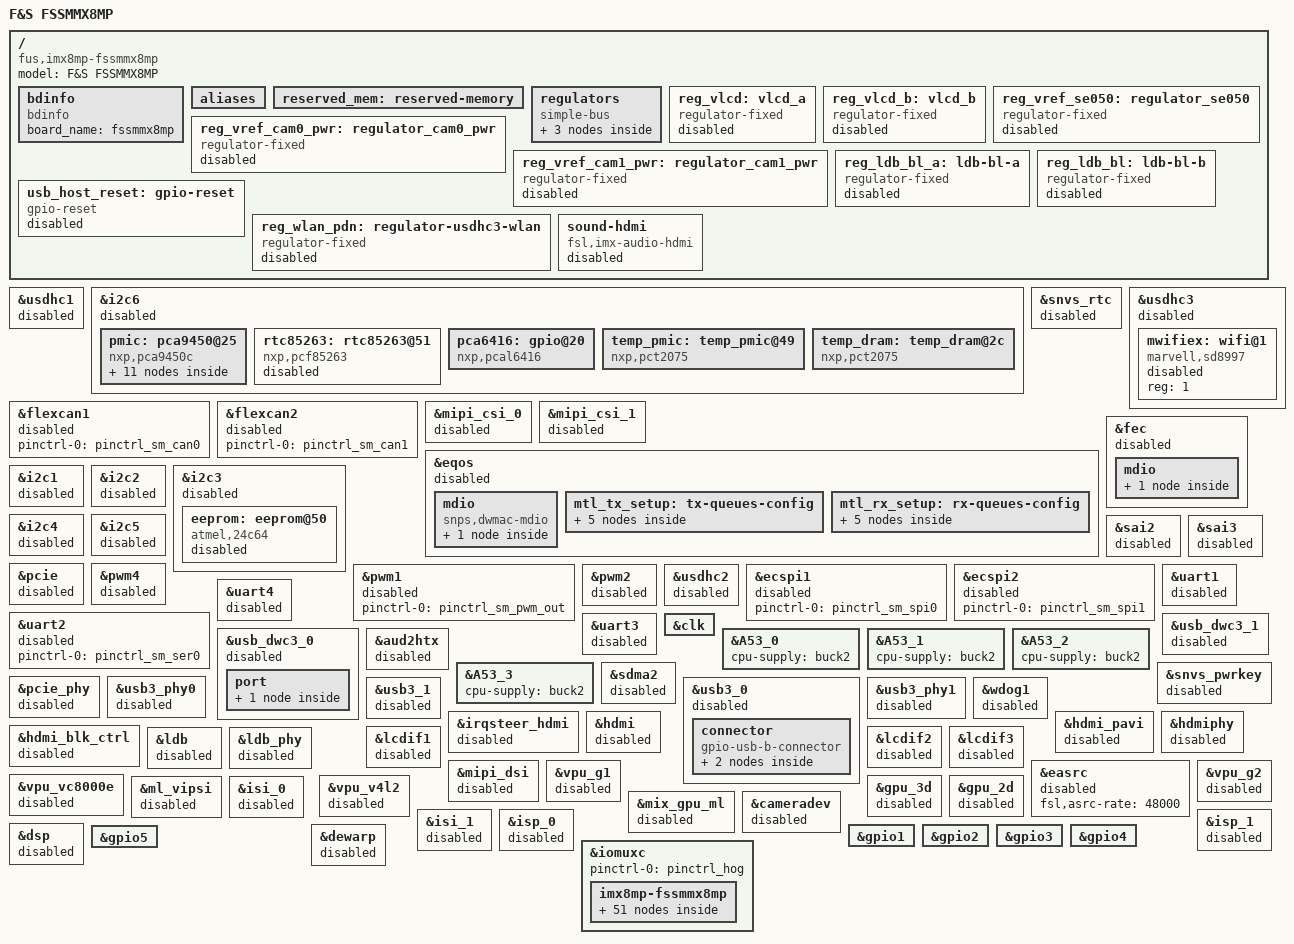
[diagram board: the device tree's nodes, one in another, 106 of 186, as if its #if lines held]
/*
 * Copyright 2024 F&S Elektronik Systeme GmbH
 *
 * This program is free software; you can redistribute it and/or modify
 * it under the terms of the GNU General Public License version 2 as
 * published by the Free Software Foundation.
 *
 * This program is distributed in the hope that it will be useful,
 * but WITHOUT ANY WARRANTY; without even the implied warranty of
 * MERCHANTABILITY or FITNESS FOR A PARTICULAR PURPOSE.  See the
 * GNU General Public License for more details.
 */

#include <dt-bindings/usb/pd.h>
#include <dt-bindings/pwm/pwm.h>
#include <dt-bindings/rtc/nxp,pcf85263.h>
#include <dt-bindings/phy/phy-imx8-pcie.h>

/* SOC-nodes to SMARC-nodes */

/* Internal nodes */
emmc: &usdhc1 {};
i2c_int: &i2c6 {};
rtc_soc: &snvs_rtc {};
sd_wlan: &usdhc3 {};

/* External nodes */
sm_can0: &flexcan1 {};
sm_can1: &flexcan2 {};
sm_csi0: &mipi_csi_0 {};
sm_csi1: &mipi_csi_1 {};
sm_gbe0: &eqos {};
sm_gbe1: &fec {};
sm_i2c_cam0: &i2c1 {};
sm_i2c_cam1: &i2c2 {};
sm_i2c_gp: &i2c3 {};
sm_i2c_pm: &i2c4 {};
sm_i2c_lcd: &i2c5 {};
sm_i2s0: &sai2 {};
sm_i2s2: &sai3 {};
sm_pcie: &pcie {};
sm_pwm_out: &pwm1 {};
sm_lcd0_bklt_pwm: &pwm4 {};
sm_lcd1_bklt_pwm: &pwm2 {};
sm_sdio: &usdhc2 {};
sm_spi0: &ecspi1 {};
sm_spi1: &ecspi2 {};
sm_ser0: &uart2 {};
sm_ser1: &uart1 {};
sm_ser2: &uart4 {};
sm_ser3: &uart3 {};
sm_usb0: &usb_dwc3_0 {};
sm_usb1: &usb_dwc3_1 {};
/* sm_usb2: sm_usb1 over HUB if mounted */
/* sm_usb3: sm_usb1 over HUB if mounted */
/* sm_usb4: sm_usb1 over HUB if mounted */

/ {
	model = "F&S FSSMMX8MP";
	compatible = "fus,imx8mp-fssmmx8mp", "fsl,imx8mp";

	bdinfo: bdinfo {
		compatible = "bdinfo";
		board_name = "fssmmx8mp";
	};

	aliases {
		ethernet0 = &eqos;
		ethernet1 = &fec;
		spi0 = &ecspi1;
		spi1 = &ecspi2;
		i2c0 = &i2c1;
		i2c1 = &i2c2;
		i2c2 = &i2c3;
		i2c3 = &i2c4;
		i2c4 = &i2c5;
		i2c5 = &i2c6;
		eeprom = &eeprom;
		wlan = &mwifiex;
		wlan-reset = &reg_wlan_pdn;
	};

	reserved_mem: reserved-memory {
		/* remove this node because the region used
		 * only by tuning tool
		 * */
		/delete-node/isp0@94400000;
		/* remove these nodes because we reserve
		 * our own memory regions
		 * */
		/delete-node/dsp@92400000;
		/delete-node/dsp_reserved_heap@93400000;
		/delete-node/vdev0vring0@942f0000;
		/delete-node/vdev0vring1@942f8000;
		/delete-node/vdev0buffer@94300000;
	};

	regulators {
		compatible = "simple-bus";
		#address-cells = <1>;
		#size-cells = <0>;

		reg_vref_1v2: regulator_1v2 {
			compatible = "regulator-fixed";
			regulator-name = "vref-1V2";
			regulator-min-microvolt = <1200000>;
			regulator-max-microvolt = <1200000>;
			regulator-always-on;
		};

		reg_vref_1v8: regulator_1v8 {
			compatible = "regulator-fixed";
			regulator-name = "vref-1V8";
			regulator-min-microvolt = <1800000>;
			regulator-max-microvolt = <1800000>;
			regulator-always-on;
		};

		reg_vref_3v3: regulator_3v3 {
			compatible = "regulator-fixed";
			regulator-name = "vref-3V3";
			regulator-min-microvolt = <3300000>;
			regulator-max-microvolt = <3300000>;
			regulator-always-on;
		};
	};

	/* LCD0 power on voltage */
	/omit-if-no-ref/
	reg_vlcd: vlcd_a {
		compatible = "regulator-fixed";
		regulator-name = "LCD0_VDD_EN";
		pinctrl-names = "default";
		pinctrl-0 = <&pinctrl_vlcd_a_on>;
		gpio = <&gpio4 20 GPIO_ACTIVE_HIGH>;
		regulator-min-microvolt = <3300000>;
		regulator-max-microvolt = <3300000>;
		enable-active-high;
		status = "disabled";
	};

	/* LCD1 power on voltage */
	/omit-if-no-ref/
	reg_vlcd_b: vlcd_b {
		compatible = "regulator-fixed";
		regulator-name = "LCD1_VDD_EN";
		pinctrl-names = "default";
		pinctrl-0 = <&pinctrl_vlcd_b_on>;
		gpio = <&gpio4 2 GPIO_ACTIVE_HIGH>;
		regulator-min-microvolt = <3300000>;
		regulator-max-microvolt = <3300000>;
		enable-active-high;
		status = "disabled";
	};

	/* SE050 power on voltage */
	reg_vref_se050: regulator_se050 {
		compatible = "regulator-fixed";
		regulator-name = "SE050_ENA";
		pinctrl-names = "default";
		pinctrl-0 = <&pinctrl_se050>;
		gpio = <&gpio1 0 GPIO_ACTIVE_HIGH>;
		regulator-min-microvolt = <1800000>;
		regulator-max-microvolt = <1800000>;
		regulator-always-on;
		enable-active-high;
		status = "disabled";
	};

	/* CAM_PWR# power on voltage */
	reg_vref_cam0_pwr: regulator_cam0_pwr {
		compatible = "regulator-fixed";
		regulator-name = "CAM0_PWR";
		pinctrl-names = "default";
		regulator-min-microvolt = <1800000>;
		regulator-max-microvolt = <1800000>;
		regulator-boot-on;
		regulator-always-on;
		status = "disabled";
	};

	/* CAM_PWR# power on voltage */
	reg_vref_cam1_pwr: regulator_cam1_pwr {
		compatible = "regulator-fixed";
		regulator-name = "CAM1_PWR";
		pinctrl-names = "default";
		regulator-min-microvolt = <1800000>;
		regulator-max-microvolt = <1800000>;
		regulator-boot-on;
		regulator-always-on;
		status = "disabled";
	};

	reg_ldb_bl_a: ldb-bl-a {
		compatible = "regulator-fixed";
		regulator-name = "ldb-bl0";
		pinctrl-names = "default";
		pinctrl-0 = <&pinctrl_ldb_bl_a>;
		gpio = <&gpio4 1 GPIO_ACTIVE_HIGH>;
		regulator-min-microvolt = <3300000>;
		regulator-max-microvolt = <3300000>;
		enable-active-high;
		status = "disabled";
	};

	reg_ldb_bl: ldb-bl-b {
		compatible = "regulator-fixed";
		regulator-name = "ldb-bl1";
		pinctrl-names = "default";
		pinctrl-0 = <&pinctrl_ldb_bl_b>;
		gpio = <&gpio4 3 GPIO_ACTIVE_HIGH>;
		regulator-min-microvolt = <3300000>;
		regulator-max-microvolt = <3300000>;
		enable-active-high;
		status = "disabled";
	};

	usb_host_reset: gpio-reset {
		compatible = "gpio-reset";
		reset-gpios = <&pca6416 14 GPIO_ACTIVE_LOW>;
		reset-delay-us = <10>;
		#reset-cells = <0>;
		status = "disabled";
	};

	reg_wlan_pdn: regulator-usdhc3-wlan {
		compatible = "regulator-fixed";
		regulator-name = "WLAN_RESET";
		pinctrl-names = "default";
		pinctrl-0 = <&pinctrl_wlan_pdn>;
		regulator-min-microvolt = <3300000>;
		regulator-max-microvolt = <3300000>;
		gpio = <&gpio4 18 GPIO_ACTIVE_HIGH>;
		off-on-delay-us = <1000>;
		enable-active-low;
		status = "disabled";
	};

	sound-hdmi {
		compatible = "fsl,imx-audio-hdmi";
		model = "audio-hdmi";
		audio-cpu = <&aud2htx>;
		hdmi-out;
		constraint-rate = <44100>, <88200>, <176400>,
				  <32000>, <48000>,
				  <96000>, <192000>;
		status = "disabled";
	};
};

&aud2htx {
	status = "disabled";
};

&clk {
	assigned-clocks = <&clk IMX8MP_CLK_A53_SRC>,
			  <&clk IMX8MP_CLK_A53_CORE>,
			  <&clk IMX8MP_CLK_NOC>,
			  <&clk IMX8MP_CLK_NOC_IO>,
			  <&clk IMX8MP_CLK_GIC>,
			  <&clk IMX8MP_CLK_AUDIO_AHB>,
			  <&clk IMX8MP_CLK_AUDIO_AXI_SRC>,
			  <&clk IMX8MP_AUDIO_PLL1>,
			  <&clk IMX8MP_AUDIO_PLL2>,
			  <&clk IMX8MP_VIDEO_PLL1>,
			  <&clk IMX8MP_CLK_CLKOUT1>;
	assigned-clock-rates = <0>, <0>,
			       <1000000000>,
			       <800000000>,
			       <500000000>,
			       <400000000>,
			       <800000000>,
			       <393216000>,
			       <361267200>,
			       <1039500000>,
			       <24576000>;

	init-on-array = <IMX8MP_CLK_HSIO_ROOT>, <IMX8MP_CLK_CLKOUT1>;
};

&A53_0 {
	cpu-supply = <&buck2>;
};

&A53_1 {
	cpu-supply = <&buck2>;
};

&A53_2 {
	cpu-supply = <&buck2>;
};

&A53_3 {
	cpu-supply = <&buck2>;
};

&sm_gbe0 {
	pinctrl-names = "default";
	pinctrl-0 = <&pinctrl_sm_gbe0>;
	phy-mode = "rgmii-id";
	phy-handle = <&ethphy0>;
	snps,force_thresh_dma_mode;
	snps,mtl-tx-config = <&mtl_tx_setup>;
	snps,mtl-rx-config = <&mtl_rx_setup>;
	status = "disabled";

	mdio {
		compatible = "snps,dwmac-mdio";
		#address-cells = <1>;
		#size-cells = <0>;

		ethphy0: ethernet-phy@4 {
			compatible = "ethernet-phy-ieee802.3-c22";
			reg = <4>;
			rtl821x,clkout-disable;
			rtl821x,aldps-enable;
			rtl821x,ssc-rxc-enable;
			rtl821x,ssc-sysclk-enable;
			rtl821x,ssc-clkout-enable;
			rtl821x,led-link = <2>; // LED2 for link indication
			rtl821x,led-act = <0>; // LED0 for activity
			reset-gpios = <&pca6416 11 GPIO_ACTIVE_LOW>;
			reset-assert-us = <10000>;
			reset-deassert-us = <100000>;
			interrupt-parent = <&gpio1>;
			interrupts = <6 IRQ_TYPE_LEVEL_LOW>;
			eee-broken-1000t;
		};
	};

	mtl_tx_setup: tx-queues-config {
		snps,tx-queues-to-use = <5>;
		snps,tx-sched-sp;

		queue0 {
			snps,dcb-algorithm;
			snps,priority = <0x1>;
		};

		queue1 {
			snps,dcb-algorithm;
			snps,priority = <0x2>;
		};

		queue2 {
			snps,dcb-algorithm;
			snps,priority = <0x4>;
		};

		queue3 {
			snps,dcb-algorithm;
			snps,priority = <0x8>;
		};

		queue4 {
			snps,dcb-algorithm;
			snps,priority = <0xf0>;
		};
	};

	mtl_rx_setup: rx-queues-config {
		snps,rx-queues-to-use = <5>;
		snps,rx-sched-sp;

		queue0 {
			snps,dcb-algorithm;
			snps,priority = <0x1>;
			snps,map-to-dma-channel = <0>;
		};

		queue1 {
			snps,dcb-algorithm;
			snps,priority = <0x2>;
			snps,map-to-dma-channel = <1>;
		};

		queue2 {
			snps,dcb-algorithm;
			snps,priority = <0x4>;
			snps,map-to-dma-channel = <2>;
		};

		queue3 {
			snps,dcb-algorithm;
			snps,priority = <0x8>;
			snps,map-to-dma-channel = <3>;
		};

		queue4 {
			snps,dcb-algorithm;
			snps,priority = <0xf0>;
			snps,map-to-dma-channel = <4>;
		};
	};
};

&sm_gbe1 {
	pinctrl-names = "default";
	pinctrl-0 = <&pinctrl_sm_gbe1>;
	phy-mode = "rgmii-id";
	phy-handle = <&ethphy1>;
	fsl,magic-packet;
	status = "disabled";

	mdio {
		#address-cells = <1>;
		#size-cells = <0>;

		ethphy1: ethernet-phy@5 {
			compatible = "ethernet-phy-ieee802.3-c22";
			reg = <5>;
			rtl821x,clkout-disable;
			rtl821x,aldps-enable;
			rtl821x,ssc-rxc-enable;
			rtl821x,ssc-sysclk-enable;
			rtl821x,ssc-clkout-enable;
			rtl821x,led-link = <2>; // LED2 for link indication
			rtl821x,led-act = <0>; // LED0 for activity
			reset-gpios = <&pca6416 12 GPIO_ACTIVE_LOW>;
			reset-assert-us = <10000>;
			reset-deassert-us = <100000>;
			interrupt-parent = <&gpio5>;
			interrupts = <1 IRQ_TYPE_LEVEL_LOW>;
			eee-broken-1000t;
		};
	};
};

#ifdef CONFIG_FSSMMX8MP_PWM_OUT
&sm_pwm_out {
	pinctrl-names = "default";
	pinctrl-0 = <&pinctrl_sm_pwm_out>;
	status = "disabled";
};
#endif /* CONFIG_FSSMMX8MP_PWM_OUT */

#ifdef CONFIG_FSSMMX8MP_LCD0_BKLT
&sm_lcd0_bklt_pwm {
	pinctrl-names = "default";
	pinctrl-0 = <&pinctrl_sm_lcd0_bklt_pwm>;
	#pwm-cells = <3>;
	keep-power;
	status = "disabled";
};
#endif /* CONFIG_FSSMMX8MP_LCD0_BKLT */

#ifdef CONFIG_FSSMMX8MP_LCD1_BKLT
&sm_lcd1_bklt_pwm {
	pinctrl-names = "default";
	pinctrl-0 = <&pinctrl_sm_lcd1_bklt_pwm>;
	#pwm-cells = <3>;
	keep-power;
	status = "disabled";
};
#endif /* CONFIG_FSSMMX8MP_LCD1_BKLT */

&snvs_pwrkey {
	status = "disabled";
};

/* Disable CPU RTC - external available */
&snvs_rtc {
	status = "disabled";
};

&sm_i2c_cam0 {
	clock-frequency = <400000>;
	pinctrl-names = "default";
	pinctrl-0 = <&pinctrl_sm_i2c_cam0>;
	status = "disabled";
};

&sm_i2c_cam1 {
	clock-frequency = <100000>;
	pinctrl-names = "default";
	pinctrl-0 = <&pinctrl_sm_i2c_cam1>;
	status = "disabled";
};

&sm_i2c_gp {
	clock-frequency = <400000>;
	pinctrl-names = "default";
	pinctrl-0 = <&pinctrl_sm_i2c_gp>;
	status = "disabled";

	/* EEPROM */
	eeprom: eeprom@50 {
		compatible = "atmel,24c64";
		reg = <0x50>;
		pagesize = <8>;
		vcc-supply = <&reg_vref_1v8>;
		status = "disabled";
	};
};

&sm_i2c_pm {
	clock-frequency = <400000>;
	pinctrl-names = "default";
	pinctrl-0 = <&pinctrl_sm_i2c_pm>;
	status = "disabled";
};

&sm_i2c_lcd {
	clock-frequency = <400000>;
	pinctrl-names = "default";
	pinctrl-0 = <&pinctrl_sm_i2c_lcd>;
	status = "disabled";
};

/* I2C_INT */
&i2c_int {
	clock-frequency = <400000>;
	pinctrl-names = "default";
	pinctrl-0 = <&pinctrl_i2c_int>;
	status = "disabled";

	pmic: pca9450@25 {
		reg = <0x25>;
		compatible = "nxp,pca9450c";
		pinctrl-names = "default";
		pinctrl-0 = <&pinctrl_pmic>;
		interrupt-parent = <&gpio4>;
		interrupts = <19 IRQ_TYPE_LEVEL_LOW>;

		regulators {
			buck1: BUCK1 {
				regulator-name = "BUCK1";
				regulator-min-microvolt = <600000>;
				regulator-max-microvolt = <2187500>;
				regulator-boot-on;
				regulator-always-on;
				regulator-ramp-delay = <3125>;
			};

			buck2: BUCK2 {
				regulator-name = "BUCK2";
				regulator-min-microvolt = <600000>;
				regulator-max-microvolt = <2187500>;
				regulator-boot-on;
				regulator-always-on;
				regulator-ramp-delay = <3125>;
				nxp,dvs-run-voltage = <950000>;
				nxp,dvs-standby-voltage = <850000>;
			};

			buck4: BUCK4 {
				regulator-name = "BUCK4";
				regulator-min-microvolt = <3300000>;
				regulator-max-microvolt = <3300000>;
				regulator-boot-on;
				regulator-always-on;
			};

			buck5: BUCK5 {
				regulator-name = "BUCK5";
				regulator-min-microvolt = <1800000>;
				regulator-max-microvolt = <1800000>;
				regulator-boot-on;
				regulator-always-on;
			};

			buck6: BUCK6 {
				regulator-name = "BUCK6";
				regulator-min-microvolt = <600000>;
				regulator-max-microvolt = <3400000>;
				regulator-boot-on;
				regulator-always-on;
			};

			ldo1: LDO1 {
				regulator-name = "LDO1";
				regulator-min-microvolt = <1600000>;
				regulator-max-microvolt = <3300000>;
				regulator-boot-on;
				regulator-always-on;
			};

			ldo2: LDO2 {
				regulator-name = "LDO";
				regulator-min-microvolt = <800000>;
				regulator-max-microvolt = <1150000>;
				regulator-boot-on;
				regulator-always-on;
			};

			ldo3: LDO3 {
				regulator-name = "LDO3";
				regulator-min-microvolt = <800000>;
				regulator-max-microvolt = <3300000>;
				regulator-boot-on;
				regulator-always-on;
			};

			ldo4: LDO4 {
				regulator-name = "LDO4";
				regulator-min-microvolt = <800000>;
				regulator-max-microvolt = <3300000>;
				regulator-boot-on;
				regulator-always-on;
			};

			ldo5: LDO5 {
				regulator-name = "LDO5";
				regulator-compatible = "ldo5";
				regulator-min-microvolt = <1800000>;
				regulator-max-microvolt = <3300000>;
				regulator-boot-on;
				regulator-always-on;
			};
		};
	};

	rtc85263: rtc85263@51 {
		compatible = "nxp,pcf85263";
		reg = <0x51>;
		clock-out = <PCF85263_CLK_OUT_32p768kHz>;

		quartz-load-capacitance = <PCF85263_QUARTZCAP_12p5pF>;
		quartz-drive-strength = <PCF85263_QUARTZDRIVE_LOW>;
		status = "disabled";
	};

	/* GPIO expander */
	pca6416: gpio@20 {
		compatible = "nxp,pcal6416";
		reg = <0x20>;
		pinctrl-names = "default";
		pinctrl-0 = <&pinctrl_pca6416>;
		vcc-supply = <&reg_vref_1v8>;
		gpio-controller;
		#gpio-cells = <2>;
		interrupt-parent = <&gpio4>;
		interrupts = <21 IRQ_TYPE_LEVEL_LOW>;
		reset-gpios = <&gpio4 22 GPIO_ACTIVE_LOW>;
		/* Enable Open-Drain for Port 0 and 1 */
		pcal6416,open-drain;
	};

	/* Temperature sensor 1 at PMIC */
	temp_pmic: temp_pmic@49 {
		compatible = "nxp,pct2075";
		reg = <0x49>;
		vs-supply = <&reg_vref_3v3>;
		#thermal-sensor-cells = <1>;
	};

	/* Temperature sensor 2 at DRAM */
	temp_dram: temp_dram@2c {
		compatible = "nxp,pct2075";
		reg = <0x2c>;
		vs-supply = <&reg_vref_3v3>;
		#thermal-sensor-cells = <1>;
	};
};

&sm_spi0 {
	#address-cells = <1>;
	#size-cells = <0>;
	pinctrl-names = "default";
	pinctrl-0 = <&pinctrl_sm_spi0>;
	status = "disabled";
};

&sm_spi1 {
	#address-cells = <1>;
	#size-cells = <0>;
	pinctrl-names = "default";
	pinctrl-0 = <&pinctrl_sm_spi1>;
	status = "disabled";
};

&sm_can0 {
	pinctrl-names = "default";
	pinctrl-0 = <&pinctrl_sm_can0>;
	status = "disabled";
};

&sm_can1 {
	pinctrl-names = "default";
	pinctrl-0 = <&pinctrl_sm_can1>;
	status = "disabled";
};

&sm_i2s0 {
	#sound-dai-cells = <0>;
	pinctrl-names = "default";
	pinctrl-0 = <&pinctrl_sm_i2s0>;
	assigned-clocks = <&clk IMX8MP_CLK_SAI2>;
	assigned-clock-parents = <&clk IMX8MP_AUDIO_PLL1_OUT>;
	assigned-clock-rates = <24576000>;
	clocks = <&audio_blk_ctrl IMX8MP_CLK_AUDIOMIX_SAI2_IPG>, <&clk IMX8MP_CLK_DUMMY>,
		 <&clk IMX8MP_CLK_CLKOUT1>, <&clk IMX8MP_CLK_DUMMY>,
		 <&clk IMX8MP_CLK_DUMMY>;
	clock-names = "bus", "mclk0", "mclk1", "mclk2", "mclk3";
	fsl,sai-mclk-direction-output;
	/* sai to clock and frame tx/rx master */
	fsl,txmasterflag = <1>; // SND_SOC_DAIFMT_CBM_CFM
	fsl,rxmasterflag = <1>; // SND_SOC_DAIFMT_CBM_CFM
	status = "disabled";
};

&sm_i2s2 {
	#sound-dai-cells = <0>;
	pinctrl-names = "default";
	pinctrl-0 = <&pinctrl_sm_i2s2>;
	assigned-clocks = <&clk IMX8MP_CLK_SAI3>;
	assigned-clock-parents = <&clk IMX8MP_AUDIO_PLL1_OUT>;
	assigned-clock-rates = <24576000>;
	clocks = <&audio_blk_ctrl IMX8MP_CLK_AUDIOMIX_SAI3_IPG>, <&clk IMX8MP_CLK_DUMMY>,
		 <&clk IMX8MP_CLK_CLKOUT1>, <&clk IMX8MP_CLK_DUMMY>,
		 <&clk IMX8MP_CLK_DUMMY>;
	clock-names = "bus", "mclk0", "mclk1", "mclk2", "mclk3";
	fsl,sai-mclk-direction-output;
	/* sai to clock and frame tx/rx master */
	fsl,txmasterflag = <1>; // SND_SOC_DAIFMT_CBM_CFM
	fsl,rxmasterflag = <1>; // SND_SOC_DAIFMT_CBM_CFM
	status = "disabled";
};

&sdma2 {
	status = "disabled";
};

&sm_ser1 {
	pinctrl-names = "default";
	pinctrl-0 = <&pinctrl_sm_ser1>;
	assigned-clocks = <&clk IMX8MP_CLK_UART1>;
	assigned-clock-parents = <&clk IMX8MP_SYS_PLL1_80M>;
	status = "disabled";
};

&sm_ser0 {
	/* console */
	pinctrl-names = "default";
	pinctrl-0 = <&pinctrl_sm_ser0>;
	status = "disabled";
};

&sm_ser3 {
	pinctrl-names = "default";
	pinctrl-0 = <&pinctrl_sm_ser3>;
	assigned-clocks = <&clk IMX8MP_CLK_UART3>;
	assigned-clock-parents = <&clk IMX8MP_SYS_PLL1_80M>;
	status = "disabled";
};

&sm_ser2 {
	pinctrl-names = "default";
	pinctrl-0 = <&pinctrl_sm_ser2>;
	assigned-clocks = <&clk IMX8MP_CLK_UART4>;
	assigned-clock-parents = <&clk IMX8MP_SYS_PLL1_80M>;
	status = "disabled";
};

&pcie {
	clkreq-gpio = <&pca6416 15 GPIO_ACTIVE_LOW>;
	reset-gpio = <&pca6416 13 GPIO_ACTIVE_LOW>;
	vpcie-supply = <&reg_vref_3v3>;
	status = "disabled";
};

&pcie_phy {
	fsl,refclk-pad-mode = <IMX8_PCIE_REFCLK_PAD_OUTPUT>;
	clocks = <&hsio_blk_ctrl>;
	clock-names = "ref";
	status = "disabled";
};

/* USB_A */
&usb3_phy0 {
	fsl,phy-tx-preemp-amp-tune = <3>;
	fsl,phy-tx-vref-tune = <0xb>;
	status = "disabled";
};

&usb3_0 {
	status = "disabled";

	connector {
		compatible = "gpio-usb-b-connector", "usb-b-connector";
		pinctrl-names = "default";
		pinctrl-0 = <&pinctrl_sm_usb0_id>;
		id-gpios = <&gpio1 10 GPIO_ACTIVE_HIGH>;

		port {
			connector_dr_sw: endpoint {
				remote-endpoint = <&usb3_drd_sw>;
			};
		};
	};
};

&sm_usb0 {
	pinctrl-names = "default";
	pinctrl-0 = <&pinctrl_sm_usb0_pwr>;
	dr_mode = "otg";
	hnp-disable;
	srp-disable;
	adp-disable;
	usb-role-switch;
	role-switch-default-mode = "none";
	status = "disabled";

	port {
		usb3_drd_sw: endpoint {
			remote-endpoint = <&connector_dr_sw>;
		};
	};
};

/* USB_B */
&usb3_phy1 {
	/* vbus-power-supply = <&ptn5110>; */
	fsl,phy-tx-vref-tune = <0xe>;
	fsl,phy-tx-preemp-amp-tune = <3>;
	fsl,phy-tx-vboost-level = <5>;
	fsl,phy-comp-dis-tune = <7>;
	fsl,pcs-tx-deemph-3p5db = <0x21>;
	fsl,phy-pcs-tx-swing-full = <0x7f>;
	status = "disabled";
};

&usb3_1 {
	status = "disabled";
};

&sm_usb1 {
	pinctrl-names = "default";
	pinctrl-0 = <&pinctrl_sm_usb1_pwr>;
	resets = <&usb_host_reset>;
	dr_mode = "host";
	status = "disabled";
};

/* SD_C - internal eMCC boot device */
&emmc {
	pinctrl-names = "default", "state_100mhz", "state_200mhz";
	pinctrl-0 = <&pinctrl_emmc>;
	pinctrl-1 = <&pinctrl_emmc_100mhz>;
	pinctrl-2 = <&pinctrl_emmc_200mhz>;
	non-removable;
	bus-width = <8>;
	status = "disabled";
};

/* SD_A - internal Micro-SD */
&sm_sdio {
	pinctrl-names = "default", "state_100mhz", "state_200mhz";
	pinctrl-0 = <&pinctrl_sm_sdio>;
	pinctrl-1 = <&pinctrl_sm_sdio_100mhz>;
	pinctrl-2 = <&pinctrl_sm_sdio_200mhz>;
	bus-width = <4>;
	status = "disabled";
};

/* SD_WLAN */
&sd_wlan {
	pinctrl-names = "default", "state_100mhz", "state_200mhz";
	pinctrl-0 = <&pinctrl_sd_wlan>;
	pinctrl-1 = <&pinctrl_sd_wlan_100mhz>;
	pinctrl-2 = <&pinctrl_sd_wlan_200mhz>;
	vmmc-supply = <&reg_wlan_pdn>;
	vqmmc-supply = <&reg_vref_1v8>;
	fsl,sdio-async-interrupt-enabled;
	pm-ignore-notify;
	keep-power-in-suspend;
	non-removable;
	cap-power-off-card;
	bus-width = <4>;
	status = "disabled";
	#address-cells = <1>;
	#size-cells = <0>;

	mwifiex: wifi@1 {
		compatible = "marvell,sd8997";
		reg = <1>;
		status = "disabled";
	};
};

&sm_csi0 {
	#address-cells = <1>;
	#size-cells = <0>;
	status = "disabled";
};

&sm_csi1 {
	#address-cells = <1>;
	#size-cells = <0>;
	status = "disabled";
};

&wdog1 {
	pinctrl-names = "default";
	pinctrl-0 = <&pinctrl_wdog>;
	fsl,ext-reset-output;
	status = "disabled";
};

&irqsteer_hdmi {
	status = "disabled";
};

&hdmi_pavi {
	status = "disabled";
};

&hdmi {
	status = "disabled";
};

&hdmiphy {
	status = "disabled";
};

&hdmi_blk_ctrl {
	status = "disabled";
};

&lcdif1 {
	status = "disabled";
};

&lcdif2 {
	status = "disabled";
};

&lcdif3 {
	status = "disabled";
	thres-low = <1 2>;             /* (FIFO * 1 / 2) */
	thres-high = <3 4>;             /* (FIFO * 3 / 4) */
};

&ldb {
	status = "disabled";
};

&ldb_phy {
	status = "disabled";
};

&mipi_dsi {
	status = "disabled";
};

&easrc {
	fsl,asrc-rate = <48000>;
	status = "disabled";
};

&vpu_g1 {
	status = "disabled";
};

&vpu_g2 {
	status = "disabled";
};

&vpu_vc8000e {
	status = "disabled";
};

&vpu_v4l2 {
	status = "disabled";
};

&gpu_3d {
	status = "disabled";
};

&gpu_2d {
	status = "disabled";
};

&ml_vipsi {
	status = "disabled";
};

&mix_gpu_ml {
	status = "disabled";
};

&cameradev {
	status = "disabled";
};

&isi_0 {
	status = "disabled";
	dma-coherent;
	bsl,dma-invalidate;
	fsl,chain_buf;
};

&isi_1 {
	status = "disabled";
	dma-coherent;
	bsl,dma-invalidate;
	fsl,chain_buf;
};

&isp_0 {
	/* remove this property because this region used
	 * only by tuning tool
	 */
	/delete-property/ memory-region;
	status = "disabled";
};

&isp_1 {
	status = "disabled";
};

&dsp {
	/delete-property/ memory-region;
	status = "disabled";
};

&dewarp {
	status = "disabled";
};

/* GPIO declarations */
&gpio1 {
	gpio-line-names =
	/* 0 */  "SE050_ENA", "WDT_TIME_OUT", "PMIC_WDOG", "SPI_B_CS1",
	/* 4 */  "SD_VSEL", "GPIO2", "ETH_A_PHY_IRQ", "GPIO1",
	/* 8 */  "GPIO3", "GPIO0", "USB_A_ID", "GPIO7",
	/* 12 */ "USB_A_PWREN_1V8", "USB_A_OC#_1V8", "USB_B_PWREN_1V8", "USB_B_OC#_1V8",
	/* 16 */ "ETH_A_RGMII_MDC", "ETH_A_RGMII_MDIO", "ETH_A_RGMII_TXD3", "ETH_A_RGMII_TXD2",
	/* 20 */ "ETH_A_RGMII_TXD1", "ETH_A_RGMII_TXD0", "ETH_A_RGMII_TXCTL", "ETH_A_RGMII_TXC",
	/* 24 */ "ETH_A_RGMII_RXCTL", "ETH_A_RGMII_RXC", "ETH_A_RGMII_RXD0", "ETH_A_RGMII_RXD1",
	/* 28 */ "ETH_A_RGMII_RXD2", "ETH_A_RGMII_RXD3", "", "";
};

&gpio2 {
	gpio-line-names =
	/* 0 */  "SD_eMMC_CLK", "SD_eMMC_CMD", "SD_eMMC_D0", "SD_eMMC_D1",
	/* 4 */  "SD_eMMC_D2", "SD_eMMC_D3", "SD_eMMC_D4", "SD_eMMC_D5",
	/* 8 */  "SD_eMMC_D6", "SD_eMMC_D7", "SD_eMMC_RST", "SD_eMMC_DS",
	/* 12 */ "SD_B_CD", "SD_B_CLK", "SD_B_CMD", "SD_B_D0",
	/* 16 */ "SD_B_D1", "SD_B_D2", "SD_B_D3", "SD_B_PWR_EN_3V3",
	/* 20 */ "SD_B_WP", "", "", "",
	/* 24 */ "", "", "", "",
	/* 28 */ "", "", "", "";
};

&gpio3 {
	gpio-line-names =
	/* 0 */  "I2S_B_CLK", "I2S_B_SDOUT", "I2C_PM_SCL", "I2C_PM_SDA",
	/* 4 */  "GPIO8", "GPIO9", "I2S_B_SDIN", "I2S_B_LRCLK",
	/* 8 */  "UART_D_RTS", "UART_D_CTS", "SD_WLAN_D0", "SD_WLAN_D1",
	/* 12 */ "SD_WLAN_D2", "SD_WLAN_D3", "GPIO12", "GPIO10",
	/* 16 */ "GPIO11", "SD_WLAN_CLK", "SD_WLAN_CMD", "I2C_INT_SCL",
	/* 20 */ "I2C_INT_SDA", "LVDS_B_BL_PWM", "CAN_A_TX", "CAN_A_RX",
	/* 24 */ "CAN_B_TX", "CAN_B_RX", "I2C_HDMI_SCL", "I2C_HDMI_SDA",
	/* 28 */ "GPIO13", "HDMI_HPD", "", "";
};

&gpio4 {
	gpio-line-names =
	/* 0 */  "RESET_OUT", "DISP_A_BL_EN", "LVDS_B_VDD_EN", "LVDS_B_BL_EN",
	/* 4 */  "ETH_B_RGMII_MDC", "ETH_B_RGMII_MDIO", "ETH_B_RGMII_RXD0", "ETH_B_RGMII_RXD1",
	/* 8 */  "ETH_B_RGMII_RXD2", "ETH_B_RGMII_RXD3", "ETH_B_RGMII_RXCTL", "ETH_B_RGMII_RXC",
	/* 12 */ "ETH_B_RGMII_TXD0", "ETH_B_RGMII_TXD1", "ETH_B_RGMII_TXD2", "ETH_B_RGMII_TXD3",
	/* 16 */ "ETH_B_RGMII_TXCTL", "ETH_B_RGMII_TXC", "WLAN_RST", "PMIC_IRQ",
	/* 20 */ "DISP_A_VDD_EN", "IOEXP_IRQ", "IOEXP_RST", "I2S_A_SDIN",
	/* 24 */ "I2S_A_LRCLK", "I2S_A_CLK", "I2S_A_SDOUT", "TEMPSENS_OS",
	/* 28 */ "GPIO4", "UART_B_RTS", "UART_B_CTS", "RTC_IRQ";
};

&gpio5 {
	gpio-line-names =
	/* 0 */  "GPIO6", "ETH_B_PHY_INT", "DISP_A_BL_PWM", "I2C_LCD_SCL",
	/* 4 */  "I2C_LCD_SDA", "GPIO5", "SPI_A_CLK", "SPI_A_MOSI",
	/* 8 */  "SPI_A_MISO", "SPI_A_CS0", "SPI_B_CLK", "SPI_B_MOSI",
	/* 12 */ "SPI_B_MISO", "SPI_B_CS0", "I2C_CAM0_SCL", "I2C_CAM0_SDA",
	/* 16 */ "I2C_CAM1_SCL", "I2C_CAM1_SDA", "I2C_GP_SCL", "I2C_GP_SDA",
	/* 20 */ "PCIe_CLKREQ", "SPI_A_CS1", "UART_A_RX", "UART_A_TX",
	/* 24 */ "UART_B_RX", "UART_B_TX", "UART_C_RX", "UART_C_TX",
	/* 28 */ "UART_D_RX", "UART_D_TX", "", "";
};

&pca6416 {
	gpio-line-names =
	/*  0 */ "BATLOW", "SMB_ALERT", "LID", "SLEEP",
	/*  4 */ "CHARGING", "CHARGER_PRSNT", "TEST", "",
	/*  8 */ "BOOT_SEL0", "BOOT_SEL1", "BOOT_SEL2", "ETH_A_PHY_RST",
	/* 12 */ "ETH_B_PHY_RST", "PCIe_RST", "USB_HUB_RST", "PCIe_WAKE";
};

&iomuxc {
	pinctrl-names = "default";
	pinctrl-0 = <&pinctrl_hog>;

	imx8mp-fssmmx8mp {
		pinctrl_hog: hoggrp {
			fsl,pins = <
				/* GPIO0 */
				MX8MP_IOMUXC_GPIO1_IO09__GPIO1_IO09			0x00014
				/* GPIO1 */
				MX8MP_IOMUXC_GPIO1_IO07__GPIO1_IO07			0x00014
				/* GPIO2 */
				MX8MP_IOMUXC_GPIO1_IO05__GPIO1_IO05			0x00014
				/* GPIO3 */
				MX8MP_IOMUXC_GPIO1_IO08__GPIO1_IO08			0x00014
				/* GPIO4 */
				MX8MP_IOMUXC_SAI3_RXFS__GPIO4_IO28			0x00014
				/* GPIO6 */
				MX8MP_IOMUXC_SAI3_TXC__GPIO5_IO00			0x00014
				/* GPIO7 */
				MX8MP_IOMUXC_GPIO1_IO11__GPIO1_IO11			0x00014
				/* GPIO8 */
				MX8MP_IOMUXC_NAND_CE3_B__GPIO3_IO04			0x00014
				/* GPIO9 */
				MX8MP_IOMUXC_NAND_CLE__GPIO3_IO05			0x00014
				/* GPIO10 */
				MX8MP_IOMUXC_NAND_RE_B__GPIO3_IO15			0x00014
				/* GPIO11 */
				MX8MP_IOMUXC_NAND_READY_B__GPIO3_IO16		0x00014
				/* GPIO12 */
				MX8MP_IOMUXC_NAND_DQS__GPIO3_IO14			0x00014
				/* GPIO13 */
				MX8MP_IOMUXC_HDMI_CEC__GPIO3_IO28			0x00014
			>;
		};

		pinctrl_se050: se050grp {
				fsl,pins = <
					MX8MP_IOMUXC_GPIO1_IO00__GPIO1_IO00			0x00012
				>;
		};

		pinctrl_hdmi_i2c: hdmi_i2cgrp {
				fsl,pins = <
					MX8MP_IOMUXC_HDMI_DDC_SCL__HDMIMIX_HDMI_SCL	0x400001c3
					MX8MP_IOMUXC_HDMI_DDC_SDA__HDMIMIX_HDMI_SDA	0x400001c3
				>;
		};

		pinctrl_hdmi_hdp: hdmi__hdpgrp {
				fsl,pins = <
					MX8MP_IOMUXC_HDMI_HPD__HDMIMIX_HDMI_HPD		0x40000019
				>;
		};

		pinctrl_touch_rst: touch_rstgrp {
			fsl,pins = <
				MX8MP_IOMUXC_GPIO1_IO01__GPIO1_IO01			0x00014
			>;
		};

		pinctrl_lvds_rst: lvds_rstgrp {
			fsl,pins = <
				MX8MP_IOMUXC_GPIO1_IO15__GPIO1_IO15			0x00014
			>;
		};

		pinctrl_ldb_bl_a: ldb_bl_agrp {
			fsl,pins = <
				/* LCD0_BL_EN / LCD0_IRQ (FSSMBB) */
				MX8MP_IOMUXC_SAI1_RXC__GPIO4_IO01			0x00144
			>;
		};

		pinctrl_ldb_bl_b: ldb_bl_bgrp {
			fsl,pins = <
				MX8MP_IOMUXC_SAI1_RXD1__GPIO4_IO03			0x00104
			>;
		};

		pinctrl_vlcd_a_on: vlcd_a_ongrp {
			fsl,pins = <
				MX8MP_IOMUXC_SAI1_MCLK__GPIO4_IO20			0x00104
			>;
		};

		pinctrl_vlcd_b_on: vlcd_b_ongrp {
			fsl,pins = <
				MX8MP_IOMUXC_SAI1_RXD0__GPIO4_IO02			0x00104
			>;
		};

		pinctrl_sm_spi0: ecspi1grp {
			fsl,pins = <
				MX8MP_IOMUXC_ECSPI1_SCLK__ECSPI1_SCLK		0x82
				MX8MP_IOMUXC_ECSPI1_MOSI__ECSPI1_MOSI		0x82
				MX8MP_IOMUXC_ECSPI1_MISO__ECSPI1_MISO		0x82
			>;
		};

		pinctrl_sm_spi0_cs: ecspi1grp-cs {
			fsl,pins = <
				MX8MP_IOMUXC_ECSPI1_SS0__ECSPI1_SS0		0x82
				MX8MP_IOMUXC_I2C4_SDA__GPIO5_IO21		0x40000
			>;
		};

		pinctrl_sm_spi1: ecspi2grp {
			fsl,pins = <
				MX8MP_IOMUXC_ECSPI2_SCLK__ECSPI2_SCLK		0x82
				MX8MP_IOMUXC_ECSPI2_MOSI__ECSPI2_MOSI		0x82
				MX8MP_IOMUXC_ECSPI2_MISO__ECSPI2_MISO		0x82
			>;
		};

		pinctrl_sm_spi1_cs: ecspi2grp-cs {
			fsl,pins = <
				MX8MP_IOMUXC_ECSPI2_SS0__ECSPI2_SS0		0x82
				MX8MP_IOMUXC_GPIO1_IO03__GPIO1_IO03		0x40000
			>;
		};

		pinctrl_sm_gbe0: eqosgrp {
			fsl,pins = <
				MX8MP_IOMUXC_ENET_MDC__ENET_QOS_MDC	0x3
				MX8MP_IOMUXC_ENET_MDIO__ENET_QOS_MDIO	0x3
				MX8MP_IOMUXC_ENET_RD0__ENET_QOS_RGMII_RD0	0x91
				MX8MP_IOMUXC_ENET_RD1__ENET_QOS_RGMII_RD1	0x11
				MX8MP_IOMUXC_ENET_RD2__ENET_QOS_RGMII_RD2	0x11
				MX8MP_IOMUXC_ENET_RD3__ENET_QOS_RGMII_RD3	0x91
				MX8MP_IOMUXC_ENET_RXC__CCM_ENET_QOS_CLOCK_GENERATE_RX_CLK	0x11
				MX8MP_IOMUXC_ENET_RX_CTL__ENET_QOS_RGMII_RX_CTL	0x11
				MX8MP_IOMUXC_ENET_TD0__ENET_QOS_RGMII_TD0		0x1f
				MX8MP_IOMUXC_ENET_TD1__ENET_QOS_RGMII_TD1		0x1f
				MX8MP_IOMUXC_ENET_TD2__ENET_QOS_RGMII_TD2		0x1f
				MX8MP_IOMUXC_ENET_TD3__ENET_QOS_RGMII_TD3		0x1f
				MX8MP_IOMUXC_ENET_TX_CTL__ENET_QOS_RGMII_TX_CTL	0x1f
				MX8MP_IOMUXC_ENET_TXC__CCM_ENET_QOS_CLOCK_GENERATE_TX_CLK	0x1f
				/* ETH_A_PHY_INTn */
				MX8MP_IOMUXC_GPIO1_IO06__GPIO1_IO06		0x39
			>;
		};

		pinctrl_sm_gbe1: fecgrp {
			fsl,pins = <
				MX8MP_IOMUXC_SAI1_RXD2__ENET1_MDC		0x3
				MX8MP_IOMUXC_SAI1_RXD3__ENET1_MDIO		0x3
				MX8MP_IOMUXC_SAI1_RXD4__ENET1_RGMII_RD0		0x91
				MX8MP_IOMUXC_SAI1_RXD5__ENET1_RGMII_RD1		0x11
				MX8MP_IOMUXC_SAI1_RXD6__ENET1_RGMII_RD2		0x11
				MX8MP_IOMUXC_SAI1_RXD7__ENET1_RGMII_RD3		0x91
				MX8MP_IOMUXC_SAI1_TXC__ENET1_RGMII_RXC		0x11
				MX8MP_IOMUXC_SAI1_TXFS__ENET1_RGMII_RX_CTL	0x11
				MX8MP_IOMUXC_SAI1_TXD0__ENET1_RGMII_TD0		0x1f
				MX8MP_IOMUXC_SAI1_TXD1__ENET1_RGMII_TD1		0x1f
				MX8MP_IOMUXC_SAI1_TXD2__ENET1_RGMII_TD2		0x1f
				MX8MP_IOMUXC_SAI1_TXD3__ENET1_RGMII_TD3		0x1f
				MX8MP_IOMUXC_SAI1_TXD4__ENET1_RGMII_TX_CTL	0x1f
				MX8MP_IOMUXC_SAI1_TXD5__ENET1_RGMII_TXC		0x1f
				/* ETH_B_PHY_INTn */
				MX8MP_IOMUXC_SAI3_TXD__GPIO5_IO01		0x39
			>;
		};

		pinctrl_sm_pwm_out: pwm1grp {
			fsl,pins = <
				MX8MP_IOMUXC_SPDIF_EXT_CLK__PWM1_OUT	0x116
			>;
		};

		pinctrl_sm_lcd0_bklt_pwm: pwm4grp {
			fsl,pins = <
				MX8MP_IOMUXC_SAI3_MCLK__PWM4_OUT	0x116
			>;
		};

		pinctrl_sm_lcd1_bklt_pwm: pwm2grp {
			fsl,pins = <
				MX8MP_IOMUXC_SAI5_RXD0__PWM2_OUT	0x116
			>;
		};

		pinctrl_sm_can0: flexcan1grp {
			fsl,pins = <
				MX8MP_IOMUXC_SAI5_RXD2__CAN1_RX		0x154
				MX8MP_IOMUXC_SAI5_RXD1__CAN1_TX		0x154
			>;
		};

		pinctrl_sm_can1: flexcan2grp {
			fsl,pins = <
				MX8MP_IOMUXC_SAI5_MCLK__CAN2_RX		0x154
				MX8MP_IOMUXC_SAI5_RXD3__CAN2_TX		0x154
			>;
		};

		pinctrl_sm_i2c_cam0: i2c1grp {
			fsl,pins = <
				MX8MP_IOMUXC_I2C1_SCL__I2C1_SCL		0x400001c3
				MX8MP_IOMUXC_I2C1_SDA__I2C1_SDA		0x400001c3
			>;
		};

		pinctrl_sm_i2c_cam1: i2c2grp {
			fsl,pins = <
				MX8MP_IOMUXC_I2C2_SCL__I2C2_SCL		0x400001c3
				MX8MP_IOMUXC_I2C2_SDA__I2C2_SDA		0x400001c3
			>;
		};

		pinctrl_sm_i2c_gp: sm_i2c_gpgrp {
			fsl,pins = <
				MX8MP_IOMUXC_I2C3_SCL__I2C3_SCL			0x400001c3
				MX8MP_IOMUXC_I2C3_SDA__I2C3_SDA			0x400001c3
			>;
		};

		pinctrl_sm_i2c_pm: i2c4grp {
			fsl,pins = <
				MX8MP_IOMUXC_NAND_CE1_B__I2C4_SCL			0x400001c3
				MX8MP_IOMUXC_NAND_CE2_B__I2C4_SDA			0x400001c3
			>;
		};

		pinctrl_sm_i2c_lcd: i2c5grp {
			fsl,pins = <
				MX8MP_IOMUXC_SPDIF_TX__I2C5_SCL			0x400001c3
				MX8MP_IOMUXC_SPDIF_RX__I2C5_SDA			0x400001c3
			>;
		};

		pinctrl_i2c_int: i2c6grp {
			fsl,pins = <
				MX8MP_IOMUXC_SAI5_RXFS__I2C6_SCL		0x400001c3
				MX8MP_IOMUXC_SAI5_RXC__I2C6_SDA			0x400001c3
			>;
		};

		pinctrl_pmic: pmicirq {
			fsl,pins = <
				MX8MP_IOMUXC_SAI1_TXD7__GPIO4_IO19	0x41
			>;
		};

		pinctrl_sm_i2s0: sai2grp {
			fsl,pins = <
				MX8MP_IOMUXC_SAI2_TXFS__AUDIOMIX_SAI2_TX_SYNC	0xd6
				MX8MP_IOMUXC_SAI2_TXC__AUDIOMIX_SAI2_TX_BCLK	0xd6
				MX8MP_IOMUXC_SAI2_TXD0__AUDIOMIX_SAI2_TX_DATA00	0xd6
				MX8MP_IOMUXC_SAI2_RXD0__AUDIOMIX_SAI2_RX_DATA00	0xd6
			>;
		};

		pinctrl_sm_i2s2: sai3grp {
			fsl,pins = <
				MX8MP_IOMUXC_NAND_DATA01__AUDIOMIX_SAI3_TX_SYNC		0xd6
				MX8MP_IOMUXC_NAND_ALE__AUDIOMIX_SAI3_TX_BCLK		0xd6
				MX8MP_IOMUXC_NAND_CE0_B__AUDIOMIX_SAI3_TX_DATA00	0xd6
				MX8MP_IOMUXC_NAND_DATA00__AUDIOMIX_SAI3_RX_DATA00	0xd6
			>;
		};

		pinctrl_sm_ser1: uart1grp {
			fsl,pins = <
				MX8MP_IOMUXC_UART1_RXD__UART1_DCE_RX 	0x140
				MX8MP_IOMUXC_UART1_TXD__UART1_DCE_TX	0x140
			>;
		};

		pinctrl_sm_ser0: uart2grp {
			fsl,pins = <
				MX8MP_IOMUXC_UART2_RXD__UART2_DCE_RX	0x140
				MX8MP_IOMUXC_UART2_TXD__UART2_DCE_TX	0x140
			>;
		};

		pinctrl_sm_ser0_rtscts: uart2grp-rtscts {
			fsl,pins = <
				MX8MP_IOMUXC_SAI3_RXC__UART2_DCE_CTS	0x140
				MX8MP_IOMUXC_SAI3_RXD__UART2_DCE_RTS	0x140
			>;
		};

		pinctrl_sm_ser3: uart3grp {
			fsl,pins = <
				MX8MP_IOMUXC_UART3_RXD__UART3_DCE_RX	0x140
				MX8MP_IOMUXC_UART3_TXD__UART3_DCE_TX	0x140
			>;
		};

		pinctrl_sm_ser2: uart4grp {
			fsl,pins = <
				MX8MP_IOMUXC_UART4_RXD__UART4_DCE_RX	0x140
				MX8MP_IOMUXC_UART4_TXD__UART4_DCE_TX	0x140
			>;
		};

		pinctrl_sm_ser2_rtscts: uart4grp-rtscts {
			fsl,pins = <
				MX8MP_IOMUXC_NAND_DATA02__UART4_DCE_CTS	0x140
				MX8MP_IOMUXC_NAND_DATA03__UART4_DCE_RTS	0x140
			>;
		};

		pinctrl_sm_usb0_pwr: usb0grp {
			fsl,pins = <
				MX8MP_IOMUXC_GPIO1_IO12__USB1_PWR	0x19
			>;
		};

		pinctrl_sm_usb0_id: usb0grp-id {
			fsl,pins = <
				MX8MP_IOMUXC_GPIO1_IO10__GPIO1_IO10	0x149
			>;
		};

		pinctrl_sm_usb1_pwr: usb1grp {
			fsl,pins = <
				MX8MP_IOMUXC_GPIO1_IO14__USB2_PWR	0x19
			>;
		};

				pinctrl_sm_sdio: usdhc2grp {
			fsl,pins = <
				MX8MP_IOMUXC_SD2_CLK__USDHC2_CLK	0x190
				MX8MP_IOMUXC_SD2_CMD__USDHC2_CMD	0x1d0
				MX8MP_IOMUXC_SD2_DATA0__USDHC2_DATA0	0x1d0
				MX8MP_IOMUXC_SD2_DATA1__USDHC2_DATA1	0x1d0
				MX8MP_IOMUXC_SD2_DATA2__USDHC2_DATA2	0x1d0
				MX8MP_IOMUXC_SD2_DATA3__USDHC2_DATA3	0x1d0
				MX8MP_IOMUXC_SD2_CD_B__USDHC2_CD_B	0x190
				MX8MP_IOMUXC_SD2_WP__USDHC2_WP	0x190
			>;
		};

		pinctrl_sm_sdio_100mhz: usdhc2grp-100mhz {
			fsl,pins = <
				MX8MP_IOMUXC_SD2_CLK__USDHC2_CLK	0x194
				MX8MP_IOMUXC_SD2_CMD__USDHC2_CMD	0x1d4
				MX8MP_IOMUXC_SD2_DATA0__USDHC2_DATA0	0x1d4
				MX8MP_IOMUXC_SD2_DATA1__USDHC2_DATA1	0x1d4
				MX8MP_IOMUXC_SD2_DATA2__USDHC2_DATA2	0x1d4
				MX8MP_IOMUXC_SD2_DATA3__USDHC2_DATA3	0x1d4
				MX8MP_IOMUXC_SD2_CD_B__USDHC2_CD_B	0x194
				MX8MP_IOMUXC_SD2_WP__USDHC2_WP	0x194
			>;
		};

		pinctrl_sm_sdio_200mhz: usdhc2grp-200mhz {
			fsl,pins = <
				MX8MP_IOMUXC_SD2_CLK__USDHC2_CLK	0x196
				MX8MP_IOMUXC_SD2_CMD__USDHC2_CMD	0x1d6
				MX8MP_IOMUXC_SD2_DATA0__USDHC2_DATA0	0x1d6
				MX8MP_IOMUXC_SD2_DATA1__USDHC2_DATA1	0x1d6
				MX8MP_IOMUXC_SD2_DATA2__USDHC2_DATA2	0x1d6
				MX8MP_IOMUXC_SD2_DATA3__USDHC2_DATA3	0x1d6
				MX8MP_IOMUXC_SD2_CD_B__USDHC2_CD_B	0x196
				MX8MP_IOMUXC_SD2_WP__USDHC2_WP	0x196
			>;
		};

		pinctrl_emmc: usdhc1grp {
			fsl,pins = <
				MX8MP_IOMUXC_SD1_CLK__USDHC1_CLK	0x190
				MX8MP_IOMUXC_SD1_CMD__USDHC1_CMD	0x1d0
				MX8MP_IOMUXC_SD1_DATA0__USDHC1_DATA0	0x1d0
				MX8MP_IOMUXC_SD1_DATA1__USDHC1_DATA1	0x1d0
				MX8MP_IOMUXC_SD1_DATA2__USDHC1_DATA2	0x1d0
				MX8MP_IOMUXC_SD1_DATA3__USDHC1_DATA3	0x1d0
				MX8MP_IOMUXC_SD1_DATA4__USDHC1_DATA4	0x1d0
				MX8MP_IOMUXC_SD1_DATA5__USDHC1_DATA5	0x1d0
				MX8MP_IOMUXC_SD1_DATA6__USDHC1_DATA6	0x1d0
				MX8MP_IOMUXC_SD1_DATA7__USDHC1_DATA7	0x1d0
				MX8MP_IOMUXC_SD1_STROBE__USDHC1_STROBE  0x190
				MX8MP_IOMUXC_SD1_RESET_B__USDHC1_RESET_B 0x144
			>;
		};

		pinctrl_emmc_100mhz: usdhc1grp-100mhz {
			fsl,pins = <
				MX8MP_IOMUXC_SD1_CLK__USDHC1_CLK	0x194
				MX8MP_IOMUXC_SD1_CMD__USDHC1_CMD	0x1d4
				MX8MP_IOMUXC_SD1_DATA0__USDHC1_DATA0	0x1d4
				MX8MP_IOMUXC_SD1_DATA1__USDHC1_DATA1	0x1d4
				MX8MP_IOMUXC_SD1_DATA2__USDHC1_DATA2	0x1d4
				MX8MP_IOMUXC_SD1_DATA3__USDHC1_DATA3	0x1d4
				MX8MP_IOMUXC_SD1_DATA4__USDHC1_DATA4	0x1d4
				MX8MP_IOMUXC_SD1_DATA5__USDHC1_DATA5	0x1d4
				MX8MP_IOMUXC_SD1_DATA6__USDHC1_DATA6	0x1d4
				MX8MP_IOMUXC_SD1_DATA7__USDHC1_DATA7	0x1d4
				MX8MP_IOMUXC_SD1_STROBE__USDHC1_STROBE  0x194
				MX8MP_IOMUXC_SD1_RESET_B__USDHC1_RESET_B 0x144
			>;
		};

		pinctrl_emmc_200mhz: usdhc1grp-200mhz {
			fsl,pins = <
				MX8MP_IOMUXC_SD1_CLK__USDHC1_CLK	0x196
				MX8MP_IOMUXC_SD1_CMD__USDHC1_CMD	0x1d6
				MX8MP_IOMUXC_SD1_DATA0__USDHC1_DATA0	0x1d6
				MX8MP_IOMUXC_SD1_DATA1__USDHC1_DATA1	0x1d6
				MX8MP_IOMUXC_SD1_DATA2__USDHC1_DATA2	0x1d6
				MX8MP_IOMUXC_SD1_DATA3__USDHC1_DATA3	0x1d6
				MX8MP_IOMUXC_SD1_DATA4__USDHC1_DATA4	0x1d6
				MX8MP_IOMUXC_SD1_DATA5__USDHC1_DATA5	0x1d6
				MX8MP_IOMUXC_SD1_DATA6__USDHC1_DATA6	0x1d6
				MX8MP_IOMUXC_SD1_DATA7__USDHC1_DATA7	0x1d6
				MX8MP_IOMUXC_SD1_STROBE__USDHC1_STROBE  0x196
				MX8MP_IOMUXC_SD1_RESET_B__USDHC1_RESET_B 0x144
			>;
		};

		/* WLAN */
		pinctrl_sd_wlan: usdhc3grp {
			fsl,pins = <
				MX8MP_IOMUXC_NAND_WE_B__USDHC3_CLK	0x190
				MX8MP_IOMUXC_NAND_WP_B__USDHC3_CMD	0x1d0
				MX8MP_IOMUXC_NAND_DATA04__USDHC3_DATA0	0x1d0
				MX8MP_IOMUXC_NAND_DATA05__USDHC3_DATA1	0x1d0
				MX8MP_IOMUXC_NAND_DATA06__USDHC3_DATA2	0x1d0
				MX8MP_IOMUXC_NAND_DATA07__USDHC3_DATA3	0x1d0
			>;
		};

		pinctrl_sd_wlan_100mhz: usdhc3grp-100mhz {
			fsl,pins = <
				MX8MP_IOMUXC_NAND_WE_B__USDHC3_CLK	0x194
				MX8MP_IOMUXC_NAND_WP_B__USDHC3_CMD	0x1d4
				MX8MP_IOMUXC_NAND_DATA04__USDHC3_DATA0	0x1d4
				MX8MP_IOMUXC_NAND_DATA05__USDHC3_DATA1	0x1d4
				MX8MP_IOMUXC_NAND_DATA06__USDHC3_DATA2	0x1d4
				MX8MP_IOMUXC_NAND_DATA07__USDHC3_DATA3	0x1d4
			>;
		};

		pinctrl_sd_wlan_200mhz: usdhc3grp-200mhz {
			fsl,pins = <
				MX8MP_IOMUXC_NAND_WE_B__USDHC3_CLK	0x196
				MX8MP_IOMUXC_NAND_WP_B__USDHC3_CMD	0x1d6
				MX8MP_IOMUXC_NAND_DATA04__USDHC3_DATA0	0x1d6
				MX8MP_IOMUXC_NAND_DATA05__USDHC3_DATA1	0x1d6
				MX8MP_IOMUXC_NAND_DATA06__USDHC3_DATA2	0x1d6
				MX8MP_IOMUXC_NAND_DATA07__USDHC3_DATA3	0x1d6
			>;
		};

		pinctrl_wlan_pdn: usdhc3grp-pdn {
			fsl,pins = <
				MX8MP_IOMUXC_SAI1_TXD6__GPIO4_IO18	0x144
			>;
		};

		pinctrl_pca6416: pca6416grp {
			fsl,pins = <
				MX8MP_IOMUXC_SAI2_RXFS__GPIO4_IO21	0x144
				MX8MP_IOMUXC_SAI2_RXC__GPIO4_IO22	0x14
			>;
		};

		pinctrl_wdog: wdoggrp {
			fsl,pins = <
				MX8MP_IOMUXC_GPIO1_IO02__WDOG1_WDOG_B	0x1c6
			>;
		};
	};
};

